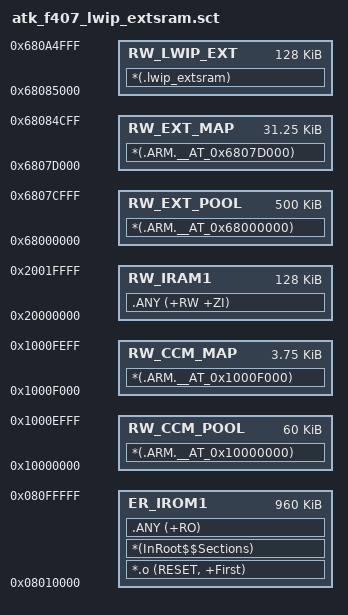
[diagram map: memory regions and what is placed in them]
; *************************************************************
; STM32F407 Scatter File (AC5)
; 目标:
; 1) 保持现有内部SRAM/Flash布局
; 2) 保持 malloc.c 中 __attribute__((at(...))) 的固定区
; 3) 将 lwIP 堆/内存池放入外部SRAM并自动连续分配
; *************************************************************
; bootloader 占用前64KB, App 从0x08010000开始 大小为0x0000F000 (960KB)，剩余的 64KB 给 bootloader 升级使用
; 调试程序的时候起始地址不要偏移，后边的大小该为 0x000100000 (1MB)，否则会导致链接错误
LR_IROM1 0x08010000 0x000F0000  {    

  ER_IROM1 0x08010000 0x000F0000  {  ; code + rodata
    *.o (RESET, +First)
    *(InRoot$$Sections)
    .ANY (+RO)
  }

  ; 兼容现有 at() 绝对地址区(来自 malloc.c)
  RW_CCM_POOL 0x10000000 0x0000F000 {
    *(.ARM.__AT_0x10000000)
  }

  RW_CCM_MAP 0x1000F000 0x00000F00 {
    *(.ARM.__AT_0x1000F000)
  }

  RW_EXT_POOL 0x68000000 0x0007D000 {
    *(.ARM.__AT_0x68000000)
  }

  RW_EXT_MAP 0x6807D000 0x00007D00 {
    *(.ARM.__AT_0x6807D000)
  }

  ; 外部SRAM给 lwIP 使用(适中): 0x68085000 ~ 0x680A4FFF (0x20000, 128KB)
  ; 这里由链接器自动顺序放置，不需要手工给每个池计算地址
  RW_LWIP_EXT 0x68085000 0x00020000 {
    *(.lwip_extsram)
  }

  ; 普通可读写数据放内部SRAM(放在最后, 避免 .ANY 抢占 lwIP 外部段)
  RW_IRAM1 0x20000000 0x00020000  {  ; 128KB SRAM
    .ANY (+RW +ZI)
  }
}
